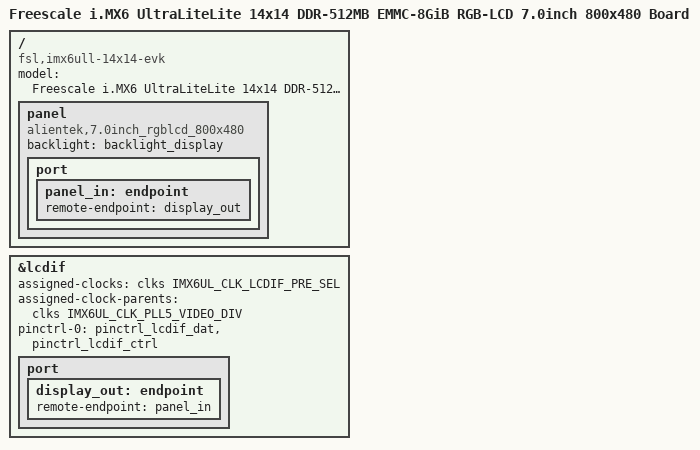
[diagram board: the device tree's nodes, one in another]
// SPDX-License-Identifier: (GPL-2.0 OR MIT)
//
// Copyright (C) 2016 Freescale Semiconductor, Inc.

/dts-v1/;

#include "imx6ull-14x14-aure-emmc.dtsi"

/ {
	model = "Freescale i.MX6 UltraLiteLite 14x14 DDR-512MB EMMC-8GiB RGB-LCD 7.0inch 800x480 Board";
	compatible = "fsl,imx6ull-14x14-evk", "fsl,imx6ull";

	panel {
		compatible = "alientek,7.0inch_rgblcd_800x480";
		backlight = <&backlight_display>;

		port {
			panel_in: endpoint {
				remote-endpoint = <&display_out>;
			};
		};
	};
};

&lcdif {
	assigned-clocks = <&clks IMX6UL_CLK_LCDIF_PRE_SEL>;
	assigned-clock-parents = <&clks IMX6UL_CLK_PLL5_VIDEO_DIV>;
	pinctrl-names = "default";
	pinctrl-0 = <&pinctrl_lcdif_dat &pinctrl_lcdif_ctrl>;
	status = "okay";

	port {
		display_out: endpoint {
			remote-endpoint = <&panel_in>;
		};
	};
};

/*&lcdif {
	assigned-clocks = <&clks IMX6UL_CLK_LCDIF_PRE_SEL>;
	assigned-clock-parents = <&clks IMX6UL_CLK_PLL5_VIDEO_DIV>;
	pinctrl-names = "default";
	pinctrl-0 = <&pinctrl_lcdif_dat &pinctrl_lcdif_ctrl>;
	display = <&display0>;
	status = "okay";

	display0: display@0 {
		bits-per-pixel = <16>;
		bus-width = <24>;

		display-timings {
			native-mode = <&timing0>;

			timing0: timing0 {
				clock-frequency = <35500000>;
				hactive = <800>;
				vactive = <480>;
				hfront-porch = <210>;
				hback-porch = <46>;
				hsync-len = <20>;
				vback-porch = <23>;
				vfront-porch = <22>;
				vsync-len = <3>;
				hsync-active = <0>;
				vsync-active = <0>;
				de-active = <1>;
				pixelclk-active = <0>;
			};
		};
	};
};*/
